VERSION ""

NS_ :

BS_:

BU_: GW Engine
VAL_TABLE_ VT_PCAN_Boolean 1 "TRUE" 0 "FALSE" ;

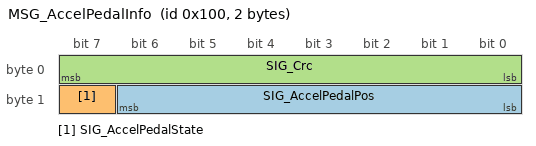
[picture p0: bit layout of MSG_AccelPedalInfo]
BO_ 256 MSG_AccelPedalInfo: 2 Engine
 SG_ SIG_AccelPedalPos : 8|7@1+ (1,0) [0|100] "%"  GW
 SG_ SIG_AccelPedalState : 15|1@1+ (1,0) [0|1] ""  GW
 SG_ SIG_Crc : 0|8@1+ (1,0) [0|255] ""  GW

BO_ 0 MSG_VehicleSpeedInfo: 2 Engine
 SG_ SIG_VehicleSpeed : 8|8@1+ (1,0) [0|250] "km/h"  GW
 SG_ SIG_Crc : 0|8@1+ (1,0) [0|255] ""  GW

VAL_ 256 SIG_AccelPedalState 1 "TRUE" 0 "FALSE" ;
